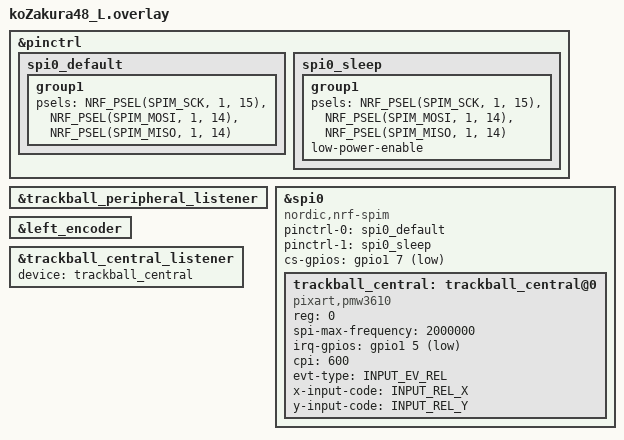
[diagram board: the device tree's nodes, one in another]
#include "koZakura48.dtsi"
#include <input/processors.dtsi>
#include <zephyr/dt-bindings/input/input-event-codes.h>

&pinctrl {
    spi0_default: spi0_default {
        group1 {
            psels = <NRF_PSEL(SPIM_SCK, 1, 15)>,
                <NRF_PSEL(SPIM_MOSI, 1, 14)>,
                <NRF_PSEL(SPIM_MISO, 1, 14)>;
        };
    };

    spi0_sleep: spi0_sleep {
        group1 {
            psels = <NRF_PSEL(SPIM_SCK, 1, 15)>,
                <NRF_PSEL(SPIM_MOSI, 1, 14)>,
                <NRF_PSEL(SPIM_MISO, 1, 14)>;
            low-power-enable;
        };
    };
};

&trackball_peripheral_listener {
    status = "okay";
};

&spi0 {
    status = "okay";
    compatible = "nordic,nrf-spim";
    pinctrl-0 = <&spi0_default>;
    pinctrl-1 = <&spi0_sleep>;
    pinctrl-names = "default", "sleep";
    cs-gpios = <&gpio1 7 GPIO_ACTIVE_LOW>;

    trackball_central: trackball_central@0 {
        status = "okay";
        compatible = "pixart,pmw3610";
        reg = <0>;
        spi-max-frequency = <2000000>;
        irq-gpios = <&gpio1 5 (GPIO_ACTIVE_LOW | GPIO_PULL_UP)>;
        cpi = <600>;
        evt-type = <INPUT_EV_REL>;
        x-input-code = <INPUT_REL_X>;
        y-input-code = <INPUT_REL_Y>;
    };
};

&left_encoder {
    status = "okay";
};

&trackball_central_listener {
    status = "okay";
    device = <&trackball_central>;
};


